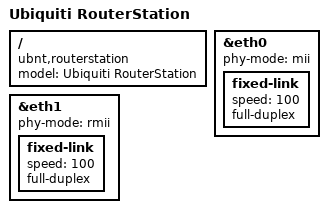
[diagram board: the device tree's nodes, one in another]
// SPDX-License-Identifier: GPL-2.0-or-later OR MIT
/dts-v1/;

#include "ar7161_ubnt_routerstation.dtsi"

/ {
	compatible = "ubnt,routerstation", "qca,ar7161";
	model = "Ubiquiti RouterStation";
};

&eth0 {
	phy-mode = "mii";

	fixed-link {
		speed = <100>;
		full-duplex;
	};
};

&eth1 {
	phy-mode = "rmii";

	fixed-link {
		speed = <100>;
		full-duplex;
	};
};
